# ESP32C3 register map
File version: 1.0
CPU: RISC-V RV32IMC single-core 1, little endian, no MPU, FPU, 3 interrupt priority bits
Registers are 32-bit, read-write, reset 0x0 unless marked. A register's access mark holds for its fields unless they carry their own. Offsets are from the block's base; [hi:lo] are bit positions.

## ASSIST_DEBUG
Base 0x600CE000
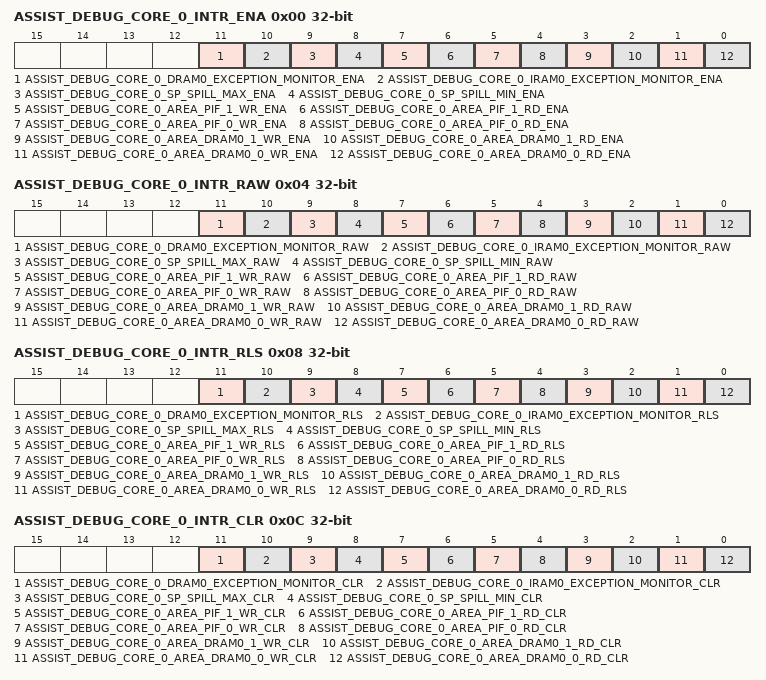
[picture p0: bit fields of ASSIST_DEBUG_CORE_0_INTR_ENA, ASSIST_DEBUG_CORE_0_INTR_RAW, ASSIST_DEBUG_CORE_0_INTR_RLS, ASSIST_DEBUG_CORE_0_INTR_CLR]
0x00 ASSIST_DEBUG_CORE_0_INTR_ENA
  [11] ASSIST_DEBUG_CORE_0_DRAM0_EXCEPTION_MONITOR_ENA, [10] ASSIST_DEBUG_CORE_0_IRAM0_EXCEPTION_MONITOR_ENA, [9] ASSIST_DEBUG_CORE_0_SP_SPILL_MAX_ENA, [8] ASSIST_DEBUG_CORE_0_SP_SPILL_MIN_ENA, [7] ASSIST_DEBUG_CORE_0_AREA_PIF_1_WR_ENA, [6] ASSIST_DEBUG_CORE_0_AREA_PIF_1_RD_ENA, [5] ASSIST_DEBUG_CORE_0_AREA_PIF_0_WR_ENA, [4] ASSIST_DEBUG_CORE_0_AREA_PIF_0_RD_ENA, [3] ASSIST_DEBUG_CORE_0_AREA_DRAM0_1_WR_ENA, [2] ASSIST_DEBUG_CORE_0_AREA_DRAM0_1_RD_ENA, [1] ASSIST_DEBUG_CORE_0_AREA_DRAM0_0_WR_ENA, [0] ASSIST_DEBUG_CORE_0_AREA_DRAM0_0_RD_ENA
0x04 ASSIST_DEBUG_CORE_0_INTR_RAW ro
  [11] ASSIST_DEBUG_CORE_0_DRAM0_EXCEPTION_MONITOR_RAW, [10] ASSIST_DEBUG_CORE_0_IRAM0_EXCEPTION_MONITOR_RAW, [9] ASSIST_DEBUG_CORE_0_SP_SPILL_MAX_RAW, [8] ASSIST_DEBUG_CORE_0_SP_SPILL_MIN_RAW, [7] ASSIST_DEBUG_CORE_0_AREA_PIF_1_WR_RAW, [6] ASSIST_DEBUG_CORE_0_AREA_PIF_1_RD_RAW, [5] ASSIST_DEBUG_CORE_0_AREA_PIF_0_WR_RAW, [4] ASSIST_DEBUG_CORE_0_AREA_PIF_0_RD_RAW, [3] ASSIST_DEBUG_CORE_0_AREA_DRAM0_1_WR_RAW, [2] ASSIST_DEBUG_CORE_0_AREA_DRAM0_1_RD_RAW, [1] ASSIST_DEBUG_CORE_0_AREA_DRAM0_0_WR_RAW, [0] ASSIST_DEBUG_CORE_0_AREA_DRAM0_0_RD_RAW
0x08 ASSIST_DEBUG_CORE_0_INTR_RLS
  [11] ASSIST_DEBUG_CORE_0_DRAM0_EXCEPTION_MONITOR_RLS, [10] ASSIST_DEBUG_CORE_0_IRAM0_EXCEPTION_MONITOR_RLS, [9] ASSIST_DEBUG_CORE_0_SP_SPILL_MAX_RLS, [8] ASSIST_DEBUG_CORE_0_SP_SPILL_MIN_RLS, [7] ASSIST_DEBUG_CORE_0_AREA_PIF_1_WR_RLS, [6] ASSIST_DEBUG_CORE_0_AREA_PIF_1_RD_RLS, [5] ASSIST_DEBUG_CORE_0_AREA_PIF_0_WR_RLS, [4] ASSIST_DEBUG_CORE_0_AREA_PIF_0_RD_RLS, [3] ASSIST_DEBUG_CORE_0_AREA_DRAM0_1_WR_RLS, [2] ASSIST_DEBUG_CORE_0_AREA_DRAM0_1_RD_RLS, [1] ASSIST_DEBUG_CORE_0_AREA_DRAM0_0_WR_RLS, [0] ASSIST_DEBUG_CORE_0_AREA_DRAM0_0_RD_RLS
0x0C ASSIST_DEBUG_CORE_0_INTR_CLR
  [11] ASSIST_DEBUG_CORE_0_DRAM0_EXCEPTION_MONITOR_CLR, [10] ASSIST_DEBUG_CORE_0_IRAM0_EXCEPTION_MONITOR_CLR, [9] ASSIST_DEBUG_CORE_0_SP_SPILL_MAX_CLR, [8] ASSIST_DEBUG_CORE_0_SP_SPILL_MIN_CLR, [7] ASSIST_DEBUG_CORE_0_AREA_PIF_1_WR_CLR, [6] ASSIST_DEBUG_CORE_0_AREA_PIF_1_RD_CLR, [5] ASSIST_DEBUG_CORE_0_AREA_PIF_0_WR_CLR, [4] ASSIST_DEBUG_CORE_0_AREA_PIF_0_RD_CLR, [3] ASSIST_DEBUG_CORE_0_AREA_DRAM0_1_WR_CLR, [2] ASSIST_DEBUG_CORE_0_AREA_DRAM0_1_RD_CLR, [1] ASSIST_DEBUG_CORE_0_AREA_DRAM0_0_WR_CLR, [0] ASSIST_DEBUG_CORE_0_AREA_DRAM0_0_RD_CLR
0x10 ASSIST_DEBUG_CORE_0_AREA_DRAM0_0_MIN
0x14 ASSIST_DEBUG_CORE_0_AREA_DRAM0_0_MAX
0x18 ASSIST_DEBUG_CORE_0_AREA_DRAM0_1_MIN
0x1C ASSIST_DEBUG_CORE_0_AREA_DRAM0_1_MAX
0x20 ASSIST_DEBUG_CORE_0_AREA_PIF_0_MIN
0x24 ASSIST_DEBUG_CORE_0_AREA_PIF_0_MAX
0x28 ASSIST_DEBUG_CORE_0_AREA_PIF_1_MIN
0x2C ASSIST_DEBUG_CORE_0_AREA_PIF_1_MAX
0x30 ASSIST_DEBUG_CORE_0_AREA_PC ro
0x34 ASSIST_DEBUG_CORE_0_AREA_SP ro
0x38 ASSIST_DEBUG_CORE_0_SP_MIN
0x3C ASSIST_DEBUG_CORE_0_SP_MAX
0x40 ASSIST_DEBUG_CORE_0_SP_PC ro
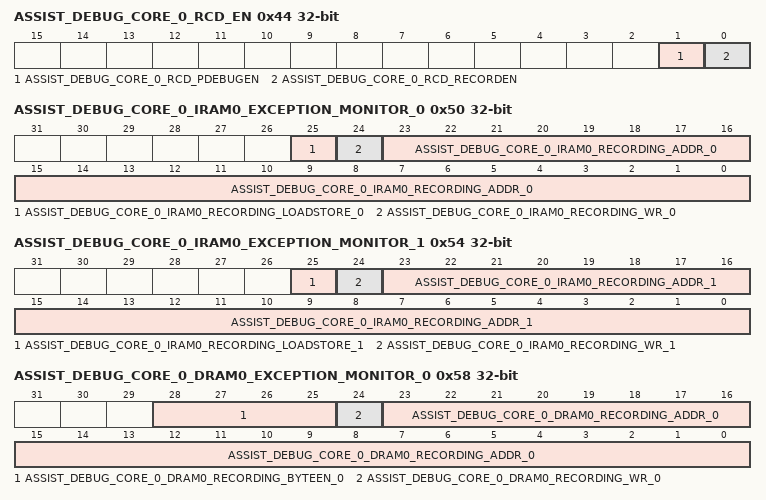
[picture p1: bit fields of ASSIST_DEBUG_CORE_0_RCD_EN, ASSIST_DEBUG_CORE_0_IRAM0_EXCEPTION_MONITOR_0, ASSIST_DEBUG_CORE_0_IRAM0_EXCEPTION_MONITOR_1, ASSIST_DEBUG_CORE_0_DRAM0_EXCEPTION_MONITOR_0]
0x44 ASSIST_DEBUG_CORE_0_RCD_EN
  [1] ASSIST_DEBUG_CORE_0_RCD_PDEBUGEN, [0] ASSIST_DEBUG_CORE_0_RCD_RECORDEN
0x48 ASSIST_DEBUG_CORE_0_RCD_PDEBUGPC ro
0x4C ASSIST_DEBUG_CORE_0_RCD_PDEBUGSP ro
0x50 ASSIST_DEBUG_CORE_0_IRAM0_EXCEPTION_MONITOR_0 ro
  [25] ASSIST_DEBUG_CORE_0_IRAM0_RECORDING_LOADSTORE_0, [24] ASSIST_DEBUG_CORE_0_IRAM0_RECORDING_WR_0, [23:0] ASSIST_DEBUG_CORE_0_IRAM0_RECORDING_ADDR_0
0x54 ASSIST_DEBUG_CORE_0_IRAM0_EXCEPTION_MONITOR_1 ro
  [25] ASSIST_DEBUG_CORE_0_IRAM0_RECORDING_LOADSTORE_1, [24] ASSIST_DEBUG_CORE_0_IRAM0_RECORDING_WR_1, [23:0] ASSIST_DEBUG_CORE_0_IRAM0_RECORDING_ADDR_1
0x58 ASSIST_DEBUG_CORE_0_DRAM0_EXCEPTION_MONITOR_0 ro
  [28:25] ASSIST_DEBUG_CORE_0_DRAM0_RECORDING_BYTEEN_0, [24] ASSIST_DEBUG_CORE_0_DRAM0_RECORDING_WR_0, [23:0] ASSIST_DEBUG_CORE_0_DRAM0_RECORDING_ADDR_0
0x5C ASSIST_DEBUG_CORE_0_DRAM0_EXCEPTION_MONITOR_1 ro
  [31:0] ASSIST_DEBUG_CORE_0_DRAM0_RECORDING_PC_0
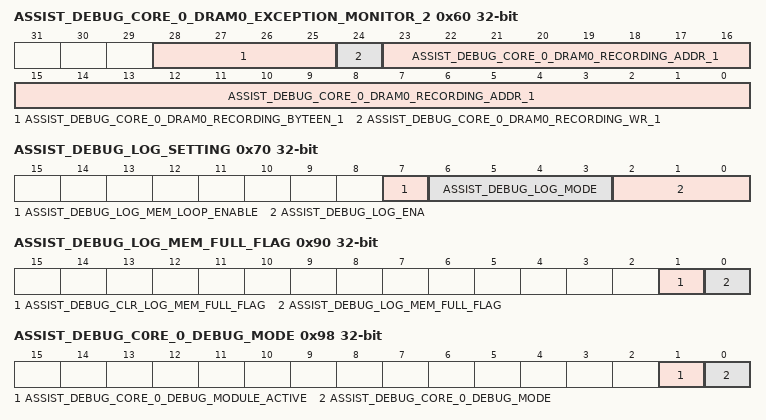
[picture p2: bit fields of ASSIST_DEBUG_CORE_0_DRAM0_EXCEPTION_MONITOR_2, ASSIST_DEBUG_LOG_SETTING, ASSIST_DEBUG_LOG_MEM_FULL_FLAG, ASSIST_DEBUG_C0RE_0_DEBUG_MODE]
0x60 ASSIST_DEBUG_CORE_0_DRAM0_EXCEPTION_MONITOR_2 ro
  [28:25] ASSIST_DEBUG_CORE_0_DRAM0_RECORDING_BYTEEN_1, [24] ASSIST_DEBUG_CORE_0_DRAM0_RECORDING_WR_1, [23:0] ASSIST_DEBUG_CORE_0_DRAM0_RECORDING_ADDR_1
0x64 ASSIST_DEBUG_CORE_0_DRAM0_EXCEPTION_MONITOR_3 ro
  [31:0] ASSIST_DEBUG_CORE_0_DRAM0_RECORDING_PC_1
0x68 ASSIST_DEBUG_CORE_X_IRAM0_DRAM0_EXCEPTION_MONITOR_0
  [19:0] ASSIST_DEBUG_CORE_X_IRAM0_DRAM0_LIMIT_CYCLE_0
0x6C ASSIST_DEBUG_CORE_X_IRAM0_DRAM0_EXCEPTION_MONITOR_1
  [19:0] ASSIST_DEBUG_CORE_X_IRAM0_DRAM0_LIMIT_CYCLE_1
0x70 ASSIST_DEBUG_LOG_SETTING
  [7] ASSIST_DEBUG_LOG_MEM_LOOP_ENABLE, [6:3] ASSIST_DEBUG_LOG_MODE, [2:0] ASSIST_DEBUG_LOG_ENA
0x74 ASSIST_DEBUG_LOG_DATA_0
0x78 ASSIST_DEBUG_LOG_DATA_MASK
  [15:0] ASSIST_DEBUG_LOG_DATA_SIZE
0x7C ASSIST_DEBUG_LOG_MIN
0x80 ASSIST_DEBUG_LOG_MAX
0x84 ASSIST_DEBUG_LOG_MEM_START
0x88 ASSIST_DEBUG_LOG_MEM_END
0x8C ASSIST_DEBUG_LOG_MEM_WRITING_ADDR ro
0x90 ASSIST_DEBUG_LOG_MEM_FULL_FLAG access per field
  [1] ASSIST_DEBUG_CLR_LOG_MEM_FULL_FLAG rw, [0] ASSIST_DEBUG_LOG_MEM_FULL_FLAG ro
0x94 ASSIST_DEBUG_C0RE_0_LASTPC_BEFORE_EXCEPTION ro
  [31:0] ASSIST_DEBUG_CORE_0_LASTPC_BEFORE_EXC
0x98 ASSIST_DEBUG_C0RE_0_DEBUG_MODE ro
  [1] ASSIST_DEBUG_CORE_0_DEBUG_MODULE_ACTIVE, [0] ASSIST_DEBUG_CORE_0_DEBUG_MODE
0x1FC ASSIST_DEBUG_DATE
  [27:0] ASSIST_DEBUG_DATE
